# ENUMTEST register map
Registers are 32-bit, read-write, reset 0xA unless marked. A register's access mark holds for its fields unless they carry their own. Offsets are from the block's base; lines under a group give offsets from that group; [hi:lo] are bit positions; {n}, {i} and the like mark numbered series; 'fields as' and 'values as' point back to an identical list; <NAME> marks a mode.

## Memory map
0x50000000 PORT — A port with modes

## PORT — A port with modes
Base 0x50000000
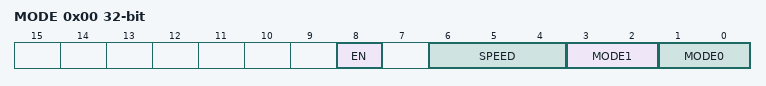
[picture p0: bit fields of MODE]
0x00 MODE — Pin modes
  [8] EN — Enable
  [6:4] SPEED — Sparse values stay a number
    0=Slow; 4=Fast
  [3:2] MODE1 — Pin 1's mode
    0=Input; 1=Output; 2=Alternate; 3=Analog
  [1:0] MODE0 — Pin 0's mode
    0=Input; 1=Output; 2=Alternate; 3=Analog
0x04 STAT ro reset 0x0 — Status
  [0] READY
